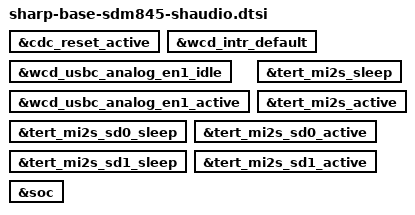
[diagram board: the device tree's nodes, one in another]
/* Copyright (c) 2017, The Linux Foundation. All rights reserved.
 *
 * This program is free software; you can redistribute it and/or modify
 * it under the terms of the GNU General Public License version 2 and
 * only version 2 as published by the Free Software Foundation.
 *
 * This program is distributed in the hope that it will be useful,
 * but WITHOUT ANY WARRANTY; without even the implied warranty of
 * MERCHANTABILITY or FITNESS FOR A PARTICULAR PURPOSE.  See the
 * GNU General Public License for more details.
 */

// only write down delete-node/property for mainDTS
/* SH_AUDIO_DRIVER -> */ /*A-001*/
&cdc_reset_active {
	/delete-node/ config;
};
&wcd_intr_default {
	/delete-node/ config;
};
&wcd_usbc_analog_en1_idle {
	/delete-node/ config;
};
&wcd_usbc_analog_en1_active {
	/delete-node/ config;
};
&tert_mi2s_sleep {
	/delete-node/ config;
};
&tert_mi2s_active {
	/delete-node/ config;
};
&tert_mi2s_sd0_sleep {
	/delete-node/ config;
};
&tert_mi2s_sd0_active {
	/delete-node/ config;
};
&tert_mi2s_sd1_sleep {
	/delete-node/ config;
};
&tert_mi2s_sd1_active {
	/delete-node/ config;
};
/* SH_AUDIO_DRIVER -> */ /*A-010*/
&soc {
	/delete-node/ wcd_usbc_analog_en1;
	/delete-node/ wcd_usbc_analog_en2;
};
/* SH_AUDIO_DRIVER <- */ /*A-010*/

/* SH_AUDIO_DRIVER <- */ /*A-001*/

